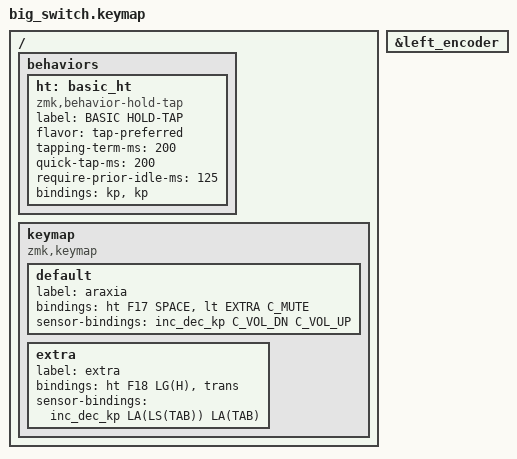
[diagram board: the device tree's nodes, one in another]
// HEADERS {{{
#include <behaviors.dtsi>
#include <dt-bindings/zmk/keys.h>
#include <dt-bindings/zmk/outputs.h>
#include <dt-bindings/zmk/bt.h>
#include <dt-bindings/zmk/rgb.h>
#include <dt-bindings/zmk/ext_power.h>

// }}}
// LAYERS {{{
#define DEFAULT  0
#define EXTRA    1
// }}}

&left_encoder {
    status = "okay";
};

/ {
// BEHAVIORS {{{
    behaviors {

        ht: basic_ht {
            compatible = "zmk,behavior-hold-tap";
            label = "BASIC HOLD-TAP";
            #binding-cells = <2>;
            flavor = "tap-preferred";
            tapping-term-ms = <200>;
            quick-tap-ms = <200>;
            require-prior-idle-ms = <125>;
            bindings = <&kp>, <&kp>;
        };

    };
// }}}
// KEYMAP {{{
// n.b. label strings are truncated after 8 characters
    keymap {
        compatible = "zmk,keymap";

        /* 0 Layer */
        default {
            label = "araxia";
            bindings = <
 &ht F17 SPACE  &lt EXTRA C_MUTE
            >;
            //sensor-bindings = <&inc_dec_kp PG_UP PG_DN>;
            sensor-bindings = <&inc_dec_kp C_VOL_DN C_VOL_UP>;
        };
        /* 1 Layer */
        extra {
            label = "extra";
            bindings = <
 &ht F18 LG(H)  &trans
            >;
            //sensor-bindings = <&inc_dec_kp PG_UP PG_DN>;
            sensor-bindings = <&inc_dec_kp LA(LS(TAB)) LA(TAB)>;
        };

    };

};
// }}}
/* vim: set ft=dts: */
